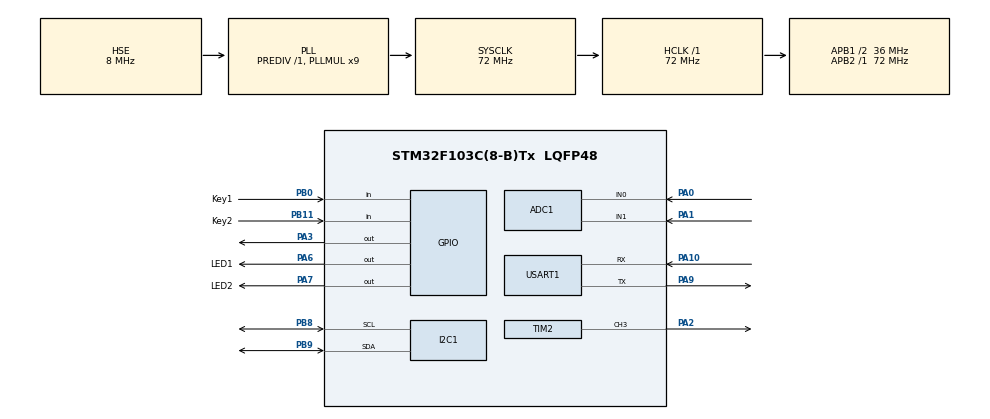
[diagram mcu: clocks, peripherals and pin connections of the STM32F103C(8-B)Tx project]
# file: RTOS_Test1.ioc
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ADC1.Channel-1\#ChannelRegularConversion=ADC_CHANNEL_0
ADC1.Channel-2\#ChannelRegularConversion=ADC_CHANNEL_1
ADC1.ContinuousConvMode=ENABLE
ADC1.EnableInjectedConversion=DISABLE
ADC1.NbrOfConversion=2
ADC1.NbrOfConversionFlag=1
ADC1.Rank-1\#ChannelRegularConversion=1
ADC1.Rank-2\#ChannelRegularConversion=2
ADC1.SamplingTime-1\#ChannelRegularConversion=ADC_SAMPLETIME_55CYCLES_5
ADC1.SamplingTime-2\#ChannelRegularConversion=ADC_SAMPLETIME_55CYCLES_5
ADC1.master=1
Dma.ADC1.0.Direction=DMA_PERIPH_TO_MEMORY
Dma.ADC1.0.Instance=DMA1_Channel1
Dma.ADC1.0.MemDataAlignment=DMA_MDATAALIGN_HALFWORD
Dma.ADC1.0.MemInc=DMA_MINC_ENABLE
Dma.ADC1.0.Mode=DMA_CIRCULAR
Dma.ADC1.0.PeriphDataAlignment=DMA_PDATAALIGN_HALFWORD
Dma.ADC1.0.PeriphInc=DMA_PINC_DISABLE
Dma.ADC1.0.Priority=DMA_PRIORITY_LOW
Dma.Request0=ADC1
FREERTOS.Queues01=sensorQueueScreen,4,12,1,Dynamic,NULL,NULL;sensorQueueComm,10,12,1,Dynamic,NULL,NULL
FREERTOS.Tasks01=InputTask,40,128,StartInputTask,As weak,NULL,Dynamic,NULL,NULL;SensorTask,32,128,StartSensorTask,As external,NULL,Dynamic,NULL,NULL;ScreenTask,16,128,StartScreenTask,As external,NULL,Dynamic,NULL,NULL;CommTask,24,256,StartCommTask,As external,NULL,Dynamic,NULL,NULL
FREERTOS.configTOTAL_HEAP_SIZE=8192
Mcu.Family=STM32F1
Mcu.Name=STM32F103C(8-B)Tx
Mcu.Package=LQFP48
NVIC.ADC1_2_IRQn=true\:5\:0\:false\:false\:true\:true\:true\:true\:true
NVIC.DMA1_Channel1_IRQn=true\:5\:0\:true\:false\:true\:true\:false\:true\:true
NVIC.PriorityGroup=NVIC_PRIORITYGROUP_4
NVIC.TIM4_IRQn=true\:15\:0\:false\:false\:true\:false\:false\:true\:true
NVIC.TimeBase=TIM4_IRQn
NVIC.TimeBaseIP=TIM4
NVIC.USART1_IRQn=true\:6\:0\:true\:false\:true\:true\:true\:true\:true
PA0-WKUP.Signal=ADCx_IN0
PA1.GPIO_Mode=GPIO_MODE_ANALOG
PA1.Signal=ADCx_IN1
PA10.Mode=Asynchronous
PA10.Signal=USART1_RX
PA13.Mode=Serial_Wire
PA13.Signal=SYS_JTMS-SWDIO
PA14.Mode=Serial_Wire
PA14.Signal=SYS_JTCK-SWCLK
PA2.Signal=S_TIM2_CH3
PA3.Signal=GPIO_Output
PA6.GPIO_Label=LED1
PA6.Signal=GPIO_Output
PA7.GPIO_Label=LED2
PA7.Signal=GPIO_Output
PA9.Mode=Asynchronous
PA9.Signal=USART1_TX
PB0.GPIO_Label=Key1
PB0.GPIO_PuPd=GPIO_PULLUP
PB0.Signal=GPIO_Input
PB11.GPIO_Label=Key2
PB11.GPIO_PuPd=GPIO_PULLUP
PB11.Signal=GPIO_Input
PB8.Mode=I2C
PB8.Signal=I2C1_SCL
PB9.Mode=I2C
PB9.Signal=I2C1_SDA
PD0-OSC_IN.Mode=HSE-External-Oscillator
PD0-OSC_IN.Signal=RCC_OSC_IN
PD1-OSC_OUT.Mode=HSE-External-Oscillator
PD1-OSC_OUT.Signal=RCC_OSC_OUT
ProjectManager.HeapSize=0x200
ProjectManager.StackSize=0x400
ProjectManager.TargetToolchain=MDK-ARM V5.32
RCC.ADCPresc=RCC_ADCPCLK2_DIV6
RCC.AHBFreq_Value=72000000
RCC.APB1CLKDivider=RCC_HCLK_DIV2
RCC.APB1Freq_Value=36000000
RCC.APB1TimFreq_Value=72000000
RCC.APB2Freq_Value=72000000
RCC.APB2TimFreq_Value=72000000
RCC.HCLKFreq_Value=72000000
RCC.PLLMUL=RCC_PLL_MUL9
RCC.PLLSourceVirtual=RCC_PLLSOURCE_HSE
RCC.SYSCLKFreq_VALUE=72000000
RCC.SYSCLKSource=RCC_SYSCLKSOURCE_PLLCLK
RCC.USBFreq_Value=72000000
SH.ADCx_IN0.0=ADC1_IN0,IN0
SH.ADCx_IN1.0=ADC1_IN1,IN1
SH.S_TIM2_CH3.0=TIM2_CH3,PWM Generation3 CH3
TIM2.Channel-PWM\ Generation3\ CH3=TIM_CHANNEL_3
TIM2.Period=999
TIM2.Prescaler=71
TIM2.Pulse-PWM\ Generation3\ CH3=500
USART1.VirtualMode=VM_ASYNC
VP_FREERTOS_VS_CMSIS_V2.Mode=CMSIS_V2
VP_SYS_VS_tim4.Mode=TIM4
VP_TIM2_VS_ClockSourceINT.Mode=Internal
board=custom

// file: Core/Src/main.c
/* USER CODE BEGIN Header */
/**
  ******************************************************************************
  * @file           : main.c
  * @brief          : Main program body
  ******************************************************************************
  * @attention
  *
  * Copyright (c) 2026 STMicroelectronics.
  * All rights reserved.
  *
  * This software is licensed under terms that can be found in the LICENSE file
  * in the root directory of this software component.
  * If no LICENSE file comes with this software, it is provided AS-IS.
  *
  ******************************************************************************
  */
/* USER CODE END Header */
#include "main.h"
#include "cmsis_os.h"
#include "adc.h"
#include "dma.h"
#include "i2c.h"
#include "tim.h"
#include "usart.h"
#include "gpio.h"

/* USER CODE BEGIN Includes */
//#include "Serial.h"
/* USER CODE END Includes */

void SystemClock_Config(void);
void MX_FREERTOS_Init(void);

int main(void)
{

  /* MCU Configuration--------------------------------------------------------*/

  /* Reset of all peripherals, Initializes the Flash interface and the Systick. */
  HAL_Init();

  /* Configure the system clock */
  SystemClock_Config();

  /* Initialize all configured peripherals */
  MX_GPIO_Init();
  MX_DMA_Init();
  MX_USART1_UART_Init();
  MX_ADC1_Init();
  MX_TIM2_Init();
  MX_I2C1_Init();
  /* USER CODE BEGIN 2 */
  //Serial_Init();
  /* USER CODE END 2 */

  /* Init scheduler */
  osKernelInitialize();  /* Call init function for freertos objects (in cmsis_os2.c) */
  MX_FREERTOS_Init();

  /* Start scheduler */
  osKernelStart();

  /* We should never get here as control is now taken by the scheduler */

  /* Infinite loop */
  while (1)
  {

  }
}

void SystemClock_Config(void)
{
  RCC_OscInitTypeDef RCC_OscInitStruct = {0};
  RCC_ClkInitTypeDef RCC_ClkInitStruct = {0};
  RCC_PeriphCLKInitTypeDef PeriphClkInit = {0};

  /** Initializes the RCC Oscillators according to the specified parameters
  * in the RCC_OscInitTypeDef structure.
  */
  RCC_OscInitStruct.OscillatorType = RCC_OSCILLATORTYPE_HSE;
  RCC_OscInitStruct.HSEState = RCC_HSE_ON;
  RCC_OscInitStruct.HSEPredivValue = RCC_HSE_PREDIV_DIV1;
  RCC_OscInitStruct.HSIState = RCC_HSI_ON;
  RCC_OscInitStruct.PLL.PLLState = RCC_PLL_ON;
  RCC_OscInitStruct.PLL.PLLSource = RCC_PLLSOURCE_HSE;
  RCC_OscInitStruct.PLL.PLLMUL = RCC_PLL_MUL9;
  if (HAL_RCC_OscConfig(&RCC_OscInitStruct) != HAL_OK)
  {
    Error_Handler();
  }

  /** Initializes the CPU, AHB and APB buses clocks
  */
  RCC_ClkInitStruct.ClockType = RCC_CLOCKTYPE_HCLK|RCC_CLOCKTYPE_SYSCLK
                              |RCC_CLOCKTYPE_PCLK1|RCC_CLOCKTYPE_PCLK2;
  RCC_ClkInitStruct.SYSCLKSource = RCC_SYSCLKSOURCE_PLLCLK;
  RCC_ClkInitStruct.AHBCLKDivider = RCC_SYSCLK_DIV1;
  RCC_ClkInitStruct.APB1CLKDivider = RCC_HCLK_DIV2;
  RCC_ClkInitStruct.APB2CLKDivider = RCC_HCLK_DIV1;

  if (HAL_RCC_ClockConfig(&RCC_ClkInitStruct, FLASH_LATENCY_2) != HAL_OK)
  {
    Error_Handler();
  }
  PeriphClkInit.PeriphClockSelection = RCC_PERIPHCLK_ADC;
  PeriphClkInit.AdcClockSelection = RCC_ADCPCLK2_DIV6;
  if (HAL_RCCEx_PeriphCLKConfig(&PeriphClkInit) != HAL_OK)
  {
    Error_Handler();
  }
}

void HAL_TIM_PeriodElapsedCallback(TIM_HandleTypeDef *htim)
{
  if (htim->Instance == TIM4)
  {
    HAL_IncTick();
  }
}

void Error_Handler(void)
{
  __disable_irq();
  while (1)
  {
  }
}

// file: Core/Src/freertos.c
/* USER CODE BEGIN Header */
/**
  ******************************************************************************
  * File Name          : freertos.c
  * Description        : Code for freertos applications
  ******************************************************************************
  * @attention
  *
  * Copyright (c) 2026 STMicroelectronics.
  * All rights reserved.
  *
  * This software is licensed under terms that can be found in the LICENSE file
  * in the root directory of this software component.
  * If no LICENSE file comes with this software, it is provided AS-IS.
  *
  ******************************************************************************
  */
/* USER CODE END Header */

#include "FreeRTOS.h"
#include "task.h"
#include "main.h"
#include "cmsis_os.h"

/* Definitions for InputTask */
osThreadId_t InputTaskHandle;
const osThreadAttr_t InputTask_attributes = {
  .name = "InputTask",
  .stack_size = 128 * 4,
  .priority = (osPriority_t) osPriorityHigh,
};
/* Definitions for SensorTask */
osThreadId_t SensorTaskHandle;
const osThreadAttr_t SensorTask_attributes = {
  .name = "SensorTask",
  .stack_size = 128 * 4,
  .priority = (osPriority_t) osPriorityAboveNormal,
};
/* Definitions for ScreenTask */
osThreadId_t ScreenTaskHandle;
const osThreadAttr_t ScreenTask_attributes = {
  .name = "ScreenTask",
  .stack_size = 128 * 4,
  .priority = (osPriority_t) osPriorityBelowNormal,
};
/* Definitions for CommTask */
osThreadId_t CommTaskHandle;
const osThreadAttr_t CommTask_attributes = {
  .name = "CommTask",
  .stack_size = 256 * 4,
  .priority = (osPriority_t) osPriorityNormal,
};
/* Definitions for sensorQueueScreen */
osMessageQueueId_t sensorQueueScreenHandle;
const osMessageQueueAttr_t sensorQueueScreen_attributes = {
  .name = "sensorQueueScreen"
};
/* Definitions for sensorQueueComm */
osMessageQueueId_t sensorQueueCommHandle;
const osMessageQueueAttr_t sensorQueueComm_attributes = {
  .name = "sensorQueueComm"
};

void StartInputTask(void *argument);
extern void StartSensorTask(void *argument);
extern void StartScreenTask(void *argument);
extern void StartCommTask(void *argument);

void MX_FREERTOS_Init(void); /* (MISRA C 2004 rule 8.1) */

void MX_FREERTOS_Init(void) {

  /* Create the queue(s) */
  /* creation of sensorQueueScreen */
  sensorQueueScreenHandle = osMessageQueueNew (4, 12, &sensorQueueScreen_attributes);

  /* creation of sensorQueueComm */
  sensorQueueCommHandle = osMessageQueueNew (10, 12, &sensorQueueComm_attributes);

  /* Create the thread(s) */
  /* creation of InputTask */
  InputTaskHandle = osThreadNew(StartInputTask, NULL, &InputTask_attributes);

  /* creation of SensorTask */
  SensorTaskHandle = osThreadNew(StartSensorTask, NULL, &SensorTask_attributes);

  /* creation of ScreenTask */
  ScreenTaskHandle = osThreadNew(StartScreenTask, NULL, &ScreenTask_attributes);

  /* creation of CommTask */
  CommTaskHandle = osThreadNew(StartCommTask, NULL, &CommTask_attributes);

}

__weak void StartInputTask(void *argument)
{
  /* USER CODE BEGIN StartInputTask */
  /* Infinite loop */
  for(;;)
  {
	HAL_GPIO_TogglePin(GPIOA,GPIO_PIN_7);
    osDelay(500);
  }
  /* USER CODE END StartInputTask */
}
